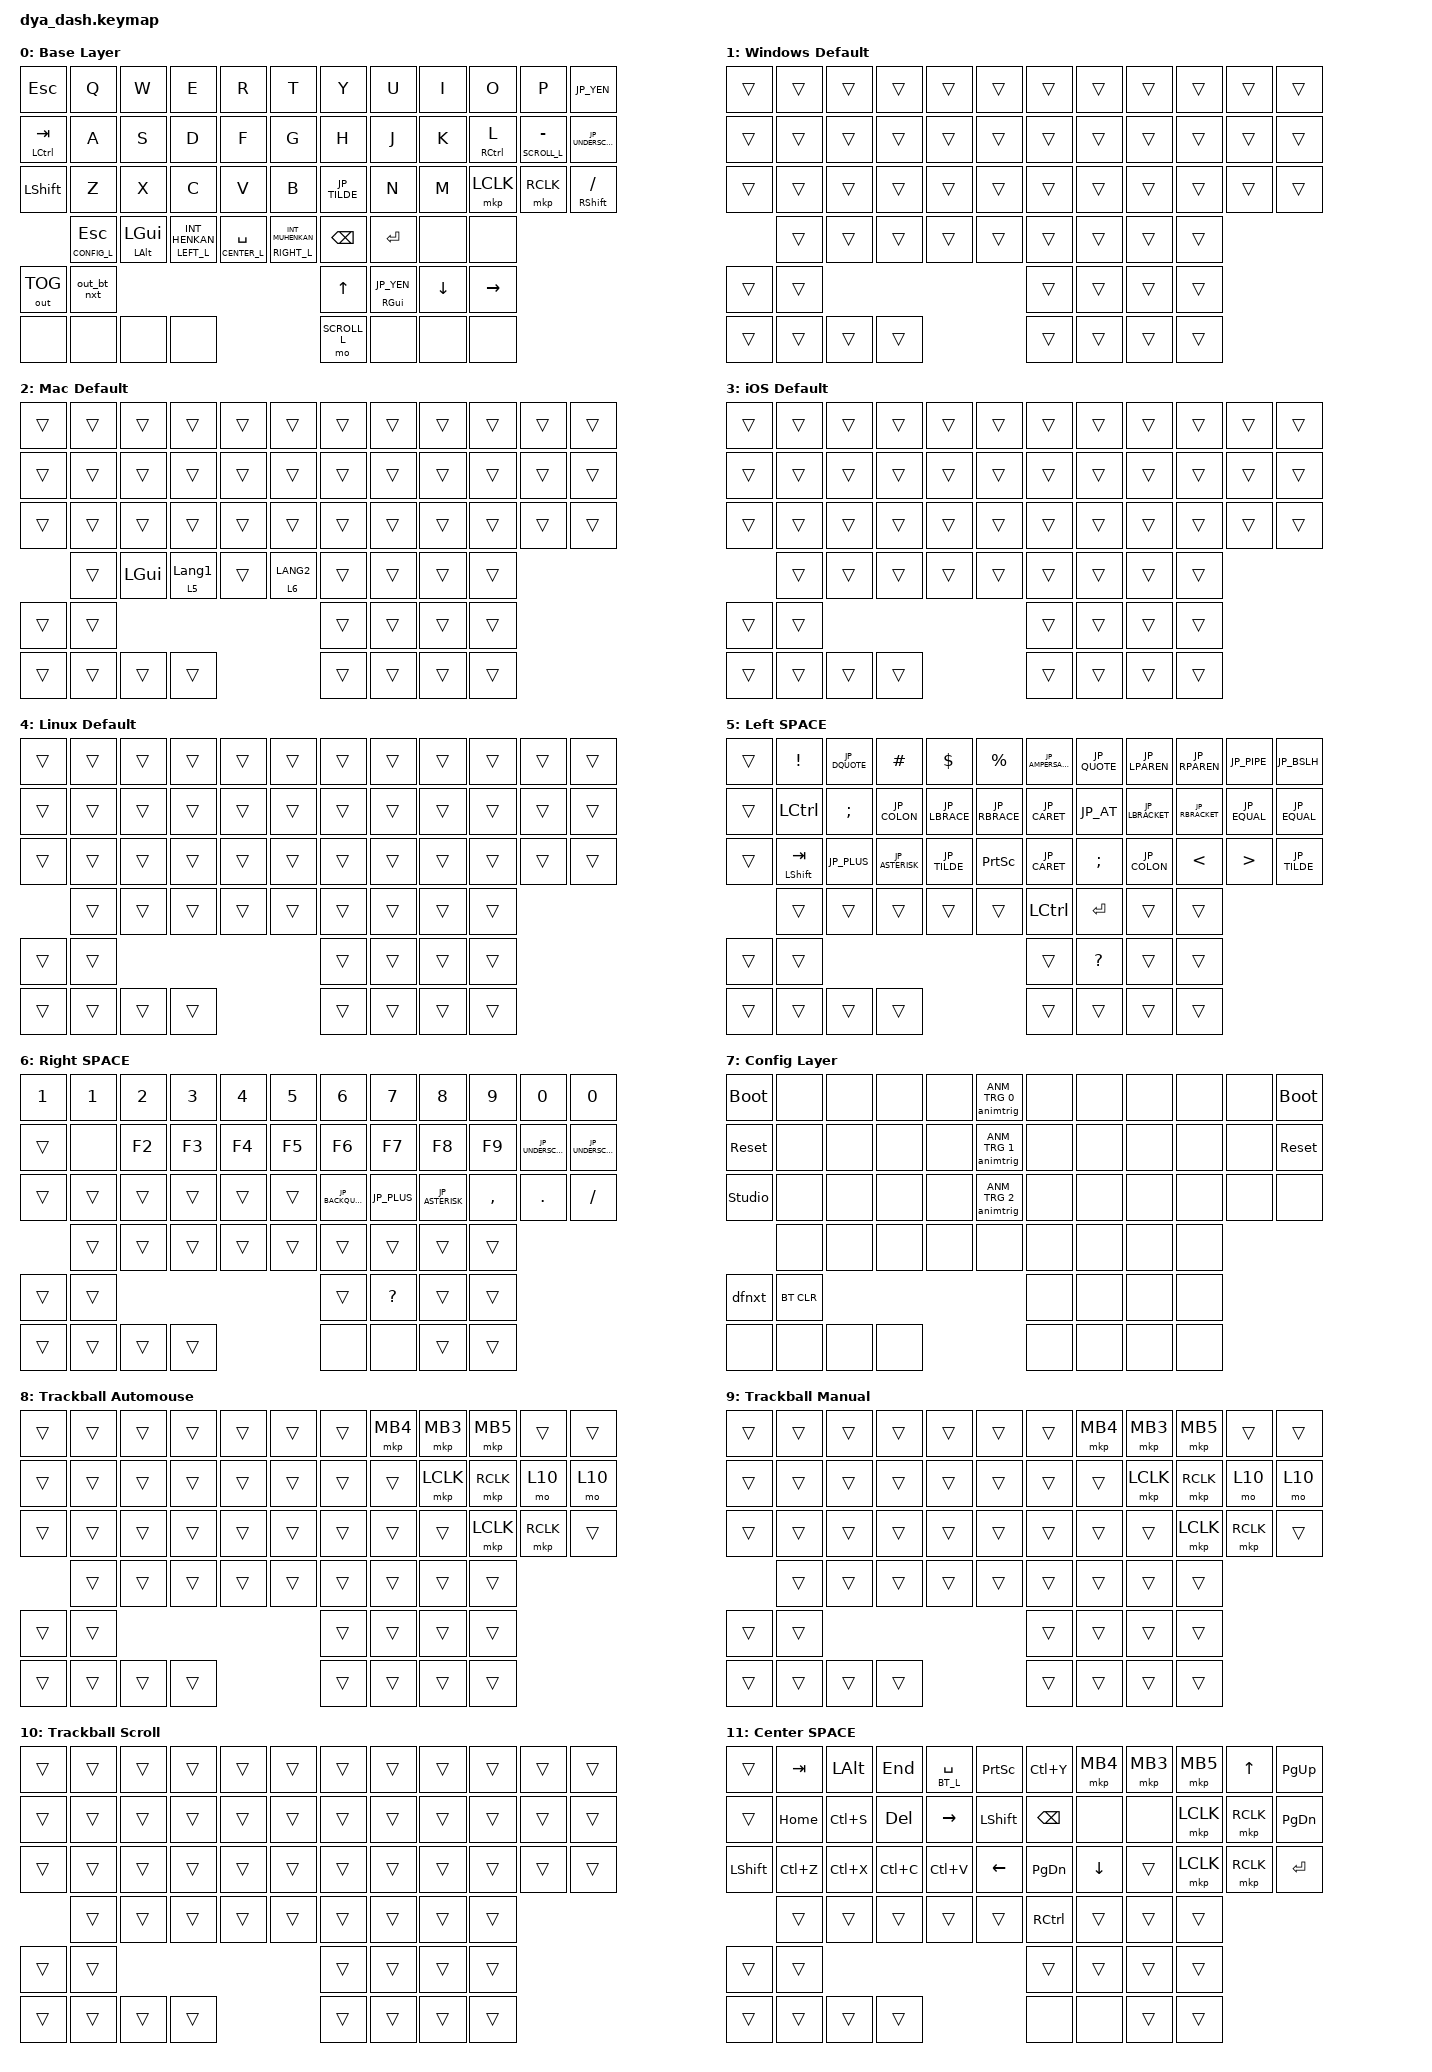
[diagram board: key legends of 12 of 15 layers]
#include <behaviors/mouse_move.dtsi>
#include <behaviors/animation_control.dtsi>
#include <behaviors/animation_trigger.dtsi>
#include <dt-bindings/zmk/mouse.h>
#include <dt-bindings/zmk_driver_animation/animation_control.h>
#include <dt-bindings/zmk_driver_animation/animation_trigger.h>
#include <dt-bindings/zmk_behavior_default_layer/default_layer.h>
#include <scroll-snap.dtsi> // スクロールスナップ用
#include <behaviors.dtsi>
#include <dt-bindings/zmk/bt.h>
#include <dt-bindings/zmk/keys.h>
#include <dt-bindings/zmk/outputs.h>
#include <dt-bindings/zmk/pointing.h>

#define JP_DQUOTE       AT                // "
#define JP_AMPERSAND    CARET             // &
#define JP_QUOTE        AMPERSAND         // '
#define JP_EQUAL        UNDER             // =
#define JP_CARET        EQUAL             // ^
#define JP_YEN          0x89              // ¥
#define JP_PLUS         COLON             // +
#define JP_TILDE        PLUS              // ~
#define JP_PIPE         LS(0x89)          // |
#define JP_AT           LEFT_BRACKET      // @
#define JP_COLON        SINGLE_QUOTE      // :
#define JP_ASTERISK     DOUBLE_QUOTES     // *
#define JP_BACKQUOTE    LEFT_BRACE        // `
#define JP_UNDERSCORE   LS(0x87)          // _
#define JP_LBRACKET     RIGHT_BRACKET     // [
#define JP_RBRACKET     BACKSLASH         // ]
#define JP_LPAREN       ASTERISK          // (
#define JP_RPAREN       LEFT_PARENTHESIS  // )
#define JP_LBRACE       RIGHT_BRACE       // {
#define JP_RBRACE       PIPE              // }
#define JP_KANA         LANGUAGE_1        // かな
#define JP_EISU         LANGUAGE_2        // 英数
#define JP_HANZEN       GRAVE             // 半角/全角
#define JP_BSLH  INT1         // (backslash)

// Layer definitions

#define DEFAULT_L		0
#define WINDOWS_L		1
#define MAC_L			2
#define IOS_L			3
#define LINUX_L			4
#define LEFT_L	 		5
#define RIGHT_L			6
#define CONFIG_L		7
#define TRACKBALL_L		8
#define TRACKBALL_L2	9
#define SCROLL_L		10
#define CENTER_L		11
#define CENTER2_L		12
#define EXT1_L			13
#define BT_L			14

// オートマウスレイヤー無効
//&trackball_listener {
//    input-processors = <
//    // TRACKBALL_L layer is activated when trackball is used.
//    // After 500ms of trackball inactivity, the layer is deactivated.
//    &zip_temp_layer TRACKBALL_L 500
//    // Example: Adjust sensitivity of trackball multiply by 1 and divide by 60.
//    // &zip_xy_scaler 1 60
//    >;
//};

&trackball_scroller {
    layers = <SCROLL_L>;

    // Example: adjust sensitivity of scroll multiply by 1 and divide by 60.

    input-processors = <
        &zip_xy_scaler 1 20
        &zip_xy_to_scroll_mapper
        &zip_scroll_snap
        &zip_scroll_transform INPUT_TRANSFORM_Y_INVERT
    >;
};

&trackball_listener_l { input-processors = <&zip_temp_layer TRACKBALL_L 500>; };

&trackball_scroller_l { layers = <SCROLL_L>; };

&zip_temp_layer { excluded-positions = <19 20 21 22 32 33 41 52 53 54 55 56 57 58 59>; };

&trackball_r { cpi = <500>; };

//&trackball_r { cpi = <800>; };

&trackball_l { cpi = <600>; };

/ {
    behaviors {
        // ctrl+h as backspace

        hbackspace: h_or_ctrl_backspace {
            compatible = "zmk,behavior-mod-morph";
            #binding-cells = <0>;
            bindings = <&kp H>, <&kp BACKSPACE>;

            mods = <(MOD_LCTL)>;
        };

        // ctrl+j as enter

        jenter: j_or_ctrl_enter {
            compatible = "zmk,behavior-mod-morph";
            #binding-cells = <0>;
            bindings = <&kp J>, <&kp ENTER>;

            mods = <(MOD_LCTL)>;
        };

        long_hold_mod_tap: long_hold_mod_tap {
            compatible = "zmk,behavior-hold-tap";
            label = "LONG_HOLD_MOD_TAP";
            bindings = <&kp>, <&kp>;

            #binding-cells = <2>;
            tapping-term-ms = <350>;
            quick-tap-ms = <0>;
            require-prior-idle-ms = <0>;
            flavor = "tap-preferred";
        };
    };

    macros {
        // Disconnect from all once for reliable connection to selected profile.
        // ZMK automatically reconnects to current profile right after disconnection.

        out_bt_nxt: out_bt_nxt {
            compatible = "zmk,behavior-macro";
            #binding-cells = <0>;
            wait-ms = <50>;
            bindings = <&out OUT_BLE &bt BT_NXT &bt BT_DISC 0 &bt BT_DISC 1 &bt BT_DISC 2 &bt BT_DISC 3 &bt BT_DISC 4>;
        };

        // Select specific BT device (0-4) and disconnect others

        out_bt_0: out_bt_0 {
            compatible = "zmk,behavior-macro";
            #binding-cells = <0>;
            wait-ms = <50>;
            bindings = <&out OUT_BLE &bt BT_SEL 0 &bt BT_DISC 1 &bt BT_DISC 2 &bt BT_DISC 3 &bt BT_DISC 4>;
        };

        out_bt_1: out_bt_1 {
            compatible = "zmk,behavior-macro";
            #binding-cells = <0>;
            wait-ms = <50>;
            bindings = <&out OUT_BLE &bt BT_SEL 1 &bt BT_DISC 0 &bt BT_DISC 2 &bt BT_DISC 3 &bt BT_DISC 4>;
        };

        out_bt_2: out_bt_2 {
            compatible = "zmk,behavior-macro";
            #binding-cells = <0>;
            wait-ms = <50>;
            bindings = <&out OUT_BLE &bt BT_SEL 2 &bt BT_DISC 0 &bt BT_DISC 1 &bt BT_DISC 3 &bt BT_DISC 4>;
        };

        out_bt_3: out_bt_3 {
            compatible = "zmk,behavior-macro";
            #binding-cells = <0>;
            wait-ms = <50>;
            bindings = <&out OUT_BLE &bt BT_SEL 3 &bt BT_DISC 0 &bt BT_DISC 1 &bt BT_DISC 2 &bt BT_DISC 4>;
        };

        out_bt_4: out_bt_4 {
            compatible = "zmk,behavior-macro";
            #binding-cells = <0>;
            wait-ms = <50>;
            bindings = <&out OUT_BLE &bt BT_SEL 4 &bt BT_DISC 0 &bt BT_DISC 1 &bt BT_DISC 2 &bt BT_DISC 3>;
        };

        // Change default layer for current profile to next layer

        dfnxt: dfnxt {
            compatible = "zmk,behavior-macro";
            #binding-cells = <0>;
            bindings = <&df DF_INC &animtrig ANM_TRG 2>;
        };
    };

    combos {
        compatible = "zmk,combos";

        // Right side's setting button shares input pin with arrow keys.
        // It works as a combo of two arrow keys.

        setting_r1 {
            timeout-ms = <10>;
            key-positions = <47 50>;
            bindings = <&kp C_VOL_DN>;
        };

        setting_r2 {
            timeout-ms = <10>;
            key-positions = <47 49>;
            bindings = <&kp C_VOL_UP>;
        };

        comma {
            bindings = <&kp COMMA>;
            key-positions = <31 32>;
            timeout-ms = <30>;
            require-prior-idle-ms = <20>;
        };

        dot {
            bindings = <&kp DOT>;
            key-positions = <32 33>;
            timeout-ms = <30>;
            require-prior-idle-ms = <20>;
        };

        asterisk {
            bindings = <&kp JP_ASTERISK>;
            key-positions = <18 19>;
            timeout-ms = <30>;
            require-prior-idle-ms = <20>;
        };

        plus {
            bindings = <&kp JP_PLUS>;
            key-positions = <30 31>;
            timeout-ms = <30>;
            require-prior-idle-ms = <20>;
        };

        mb3 {
            bindings = <&mkp MCLK>;
            key-positions = <7 8 9>;
            timeout-ms = <30>;
            require-prior-idle-ms = <20>;
        };

        mb4 {
            bindings = <&mkp MB4>;
            key-positions = <7 8>;
            timeout-ms = <30>;
        };

        mb5 {
            bindings = <&mkp MB5>;
            key-positions = <8 9>;
            timeout-ms = <30>;
            require-prior-idle-ms = <20>;
        };

        semicolon {
            bindings = <&kp SEMICOLON>;
            key-positions = <19 20>;
            timeout-ms = <30>;
            require-prior-idle-ms = <20>;
        };

        colon {
            bindings = <&kp JP_COLON>;
            key-positions = <20 21>;
            timeout-ms = <30>;
            require-prior-idle-ms = <20>;
        };

        shift_tab {
            bindings = <&kt LS(TAB)>;
            key-positions = <15 16>;
            timeout-ms = <30>;
            require-prior-idle-ms = <20>;
        };

        esc {
            bindings = <&kt ESC>;
            key-positions = <1 2>;
        };

        lctrl {
            bindings = <&kp LCTRL>;
            key-positions = <13 14>;
        };

        tab {
            bindings = <&kp TAB>;
            key-positions = <14 15>;
        };
    };

    keymap {
        compatible = "zmk,keymap";

        // template {
        //     bindings = <
        //         &trans      &trans      &trans      &trans      &trans      &trans      /**/ &trans      &trans      &trans      &trans      &trans      &trans
        //         &trans      &trans      &trans      &trans      &trans      &trans      /**/ &trans      &trans      &trans      &trans      &trans      &trans
        //         &trans      &trans      &trans      &trans      &trans      &trans      /**/ &trans      &trans      &trans      &trans      &trans      &trans
        //                     &trans      &trans      &trans      &trans      &trans      /**/ &trans      &trans      &trans      &trans
        //
        //         &trans      &trans                                                      /**/ &trans      &trans      &trans      &trans
        //         &trans      &trans      &trans      &trans                              /**/ &trans      &trans      &trans      &trans
        //     >;
        // };

        default_layer {
            display-name = "Base Layer";

            // --------------------------------------------------------------------------------------------------------------------------------------------------
            // |   TAB   |    Q    |    W    |    E       |    R    |    T        |            |    Y        |    U            |    I         |    O         |    P    |    ￥   |
            // |   CTRL  |    A    |    S    |    D       |    F    |    G        |            |    H        |    J            |    K         |    L         |    ;    |    -    |
            // |  SHIFT  |    Z    |    X    |    C       |    V    |    B        |            |    B        |    N            |    M         |    MB1       |    MB2  |    /    |
            //           |  CONFIG |   WIN   | LEFT_LAYER |  SPACE  | RIGHT_LAYER |            | BACKSPACE   |  ENTER          |   未使用     |   未使用      |
            // --------------------------------------------------------------------------------------------------------------------------------------------------
            // | BLE     |  USB    |                                                       | 未使用       | (右下)mt GUI ￥ |  未使用      |   未使用      |
            // | touch1  | touch2  | touch3  | touch 4 |                                   | touch1      | touch2          | touch3  | touch 4 |

            bindings = <
&kp ESC        &kp Q             &kp W              &kp E                  &kp R               &kp T                     &kp Y          &kp U                 &kp I     &kp O                       &kp P               &kp JP_YEN
&mt LCTRL TAB  &kp A             &kp S              &kp D                  &kp F               &kp G                     &kp H          &kp J                 &kp K     &long_hold_mod_tap RCTRL L  &lt SCROLL_L MINUS  &kp JP_UNDERSCORE
&kp LSHIFT     &kp Z             &kp X              &kp C                  &kp V               &kp B                     &kp JP_TILDE   &kp N                 &kp M     &mkp LCLK                   &mkp RCLK           &mt RIGHT_SHIFT SLASH
               &lt CONFIG_L ESC  &mt LALT LEFT_GUI  &lt LEFT_L INT_HENKAN  &lt CENTER_L SPACE  &lt RIGHT_L INT_MUHENKAN  &kp BACKSPACE  &kp ENTER             &none     &none
&out OUT_TOG   &out_bt_nxt                                                                                               &kp UP         &mt RIGHT_GUI JP_YEN  &kp DOWN  &kp RIGHT
&none          &none             &none              &none                                                                &mo SCROLL_L   &none                 &none     &none
            >;
        };

        windows_default_layer {
            display-name = "Windows Default";
            bindings = <
&trans  &trans  &trans  &trans  &trans  &trans  &trans  &trans  &trans  &trans  &trans  &trans
&trans  &trans  &trans  &trans  &trans  &trans  &trans  &trans  &trans  &trans  &trans  &trans
&trans  &trans  &trans  &trans  &trans  &trans  &trans  &trans  &trans  &trans  &trans  &trans
        &trans  &trans  &trans  &trans  &trans  &trans  &trans  &trans  &trans
&trans  &trans                                  &trans  &trans  &trans  &trans
&trans  &trans  &trans  &trans                  &trans  &trans  &trans  &trans
            >;
        };

        mac_default_layer {
            display-name = "Mac Default";
            bindings = <
&trans  &trans  &trans        &trans            &trans  &trans       &trans  &trans  &trans  &trans  &trans  &trans
&trans  &trans  &trans        &trans            &trans  &trans       &trans  &trans  &trans  &trans  &trans  &trans
&trans  &trans  &trans        &trans            &trans  &trans       &trans  &trans  &trans  &trans  &trans  &trans
        &trans  &kp LEFT_GUI  &lt 5 LANGUAGE_1  &trans  &lt 6 LANG2  &trans  &trans  &trans  &trans
&trans  &trans                                                       &trans  &trans  &trans  &trans
&trans  &trans  &trans        &trans                                 &trans  &trans  &trans  &trans
            >;
        };

        ios_default_layer {
            display-name = "iOS Default";
            bindings = <
&trans  &trans  &trans  &trans  &trans  &trans  &trans  &trans  &trans  &trans  &trans  &trans
&trans  &trans  &trans  &trans  &trans  &trans  &trans  &trans  &trans  &trans  &trans  &trans
&trans  &trans  &trans  &trans  &trans  &trans  &trans  &trans  &trans  &trans  &trans  &trans
        &trans  &trans  &trans  &trans  &trans  &trans  &trans  &trans  &trans
&trans  &trans                                  &trans  &trans  &trans  &trans
&trans  &trans  &trans  &trans                  &trans  &trans  &trans  &trans
            >;
        };

        linux_default_layer {
            display-name = "Linux Default";
            bindings = <
&trans  &trans  &trans  &trans  &trans  &trans  &trans  &trans  &trans  &trans  &trans  &trans
&trans  &trans  &trans  &trans  &trans  &trans  &trans  &trans  &trans  &trans  &trans  &trans
&trans  &trans  &trans  &trans  &trans  &trans  &trans  &trans  &trans  &trans  &trans  &trans
        &trans  &trans  &trans  &trans  &trans  &trans  &trans  &trans  &trans
&trans  &trans                                  &trans  &trans  &trans  &trans
&trans  &trans  &trans  &trans                  &trans  &trans  &trans  &trans
            >;
        };

        left_layer {
            display-name = "Left SPACE";

            // --------------------------------------------------------------------------------------------------------------------------------------------------------------------
            // |  ESC    |  !  |  @  |  #       |  $  |  %       |                           |  ^  |  &      |  *      |  (  |  )  |  \  |
            // |         |     |     |          |     |          |                           |  `  |  -      |  =      |  [  |  ]  |SHIFT|
            //           |     |     |          |     |          |                           |     |         |         |     |

            bindings = <
&trans  &kp EXCLAMATION     &kp JP_DQUOTE  &kp HASH         &kp DOLLAR     &kp PERCENT      &kp JP_AMPERSAND  &kp JP_QUOTE   &kp JP_LPAREN    &kp JP_RPAREN    &kp JP_PIPE       &kp JP_BSLH
&trans  &kp LCTRL           &kp SEMICOLON  &kp JP_COLON     &kp JP_LBRACE  &kp JP_RBRACE    &kp JP_CARET      &kp JP_AT      &kp JP_LBRACKET  &kp JP_RBRACKET  &kp JP_EQUAL      &kp JP_EQUAL
&trans  &mt LEFT_SHIFT TAB  &kp JP_PLUS    &kp JP_ASTERISK  &kp JP_TILDE   &kp PRINTSCREEN  &kp JP_CARET      &kp SEMICOLON  &kp JP_COLON     &kp LESS_THAN    &kp GREATER_THAN  &kp JP_TILDE
        &trans              &trans         &trans           &trans         &trans           &kp LCTRL         &kp ENTER      &trans           &trans
&trans  &trans                                                                              &trans            &kp QUESTION   &trans           &trans
&trans  &trans              &trans         &trans                                           &trans            &trans         &trans           &trans
            >;
        };

        right_layer {
            display-name = "Right SPACE";
            bindings = <
&kp NUMBER_1  &kp NUMBER_1  &kp NUMBER_2  &kp NUMBER_3  &kp NUMBER_4  &kp NUMBER_5  &kp NUMBER_6      &kp NUMBER_7  &kp NUMBER_8     &kp NUMBER_9  &kp NUMBER_0       &kp N0
&trans        &none         &kp F2        &kp F3        &kp F4        &kp F5        &kp F6            &kp F7        &kp F8           &kp F9        &kp JP_UNDERSCORE  &kp JP_UNDERSCORE
&trans        &trans        &trans        &trans        &trans        &trans        &kp JP_BACKQUOTE  &kp JP_PLUS   &kp JP_ASTERISK  &kp COMMA     &kp PERIOD         &kp SLASH
              &trans        &trans        &trans        &trans        &trans        &trans            &trans        &trans           &trans
&trans        &trans                                                                &trans            &kp QUESTION  &trans           &trans
&trans        &trans        &trans        &trans                                    &none             &none         &trans           &trans
            >;
        };

        config_layer {
            display-name = "Config Layer";
            bindings = <
&bootloader     &none       &none  &none  &none  &animtrig ANM_TRG 0  &none  &none  &none  &none  &none  &bootloader
&sys_reset      &none       &none  &none  &none  &animtrig ANM_TRG 1  &none  &none  &none  &none  &none  &sys_reset
&studio_unlock  &none       &none  &none  &none  &animtrig ANM_TRG 2  &none  &none  &none  &none  &none  &none
                &none       &none  &none  &none  &none                &none  &none  &none  &none
&dfnxt          &bt BT_CLR                                            &none  &none  &none  &none
&none           &none       &none  &none                              &none  &none  &none  &none
            >;
        };

        trackball_layer {
            display-name = "Trackball Automouse";
            bindings = <
&trans  &trans  &trans  &trans  &trans  &trans  &trans  &mkp MB4  &mkp MB3   &mkp MB5   &trans     &trans
&trans  &trans  &trans  &trans  &trans  &trans  &trans  &trans    &mkp LCLK  &mkp RCLK  &mo 10     &mo 10
&trans  &trans  &trans  &trans  &trans  &trans  &trans  &trans    &trans     &mkp LCLK  &mkp RCLK  &trans
        &trans  &trans  &trans  &trans  &trans  &trans  &trans    &trans     &trans
&trans  &trans                                  &trans  &trans    &trans     &trans
&trans  &trans  &trans  &trans                  &trans  &trans    &trans     &trans
            >;
        };

        trackball_layer2 {
            display-name = "Trackball Manual";
            bindings = <
&trans  &trans  &trans  &trans  &trans  &trans  &trans  &mkp MB4  &mkp MB3   &mkp MB5   &trans     &trans
&trans  &trans  &trans  &trans  &trans  &trans  &trans  &trans    &mkp LCLK  &mkp RCLK  &mo 10     &mo 10
&trans  &trans  &trans  &trans  &trans  &trans  &trans  &trans    &trans     &mkp LCLK  &mkp RCLK  &trans
        &trans  &trans  &trans  &trans  &trans  &trans  &trans    &trans     &trans
&trans  &trans                                  &trans  &trans    &trans     &trans
&trans  &trans  &trans  &trans                  &trans  &trans    &trans     &trans
            >;
        };

        scroll_layer {
            display-name = "Trackball Scroll";
            bindings = <
&trans  &trans  &trans  &trans  &trans  &trans  &trans  &trans  &trans  &trans  &trans  &trans
&trans  &trans  &trans  &trans  &trans  &trans  &trans  &trans  &trans  &trans  &trans  &trans
&trans  &trans  &trans  &trans  &trans  &trans  &trans  &trans  &trans  &trans  &trans  &trans
        &trans  &trans  &trans  &trans  &trans  &trans  &trans  &trans  &trans
&trans  &trans                                  &trans  &trans  &trans  &trans
&trans  &trans  &trans  &trans                  &trans  &trans  &trans  &trans
            >;
        };

        center_layer {
            display-name = "Center SPACE";
            bindings = <
&trans          &kp TAB    &kp LEFT_ALT  &kp END    &lt BT_L SPACE   &kp PRINTSCREEN  &kp LC(Y)      &mkp MB4        &mkp MB3  &mkp MB5   &kp UP_ARROW  &kp PAGE_UP
&trans          &kp HOME   &kp LC(S)     &kp DEL    &kp RIGHT_ARROW  &kp LEFT_SHIFT   &kp BACKSPACE  &none           &none     &mkp LCLK  &mkp RCLK     &kp PAGE_DOWN
&kp LEFT_SHIFT  &kp LC(Z)  &kp LC(X)     &kp LC(C)  &kp LC(V)        &kp LEFT_ARROW   &kp PAGE_DOWN  &kp DOWN_ARROW  &trans    &mkp LCLK  &mkp RCLK     &kp ENTER
                &trans     &trans        &trans     &trans           &trans           &kp RCTRL      &trans          &trans    &trans
&trans          &trans                                                                &trans         &trans          &trans    &trans
&trans          &trans     &trans        &trans                                       &none          &none           &trans    &trans
            >;
        };

        center2_layer {
            display-name = "Center SPACE(mac)";
            bindings = <
&trans          &kp TAB    &kp LEFT_ALT  &kp END    &lt BT_L SPACE   &kp PRINTSCREEN  &kp LC(Y)      &mkp MB4        &mkp MB3  &mkp MB5   &kp UP_ARROW  &kp PAGE_UP
&trans          &kp HOME   &kp LC(S)     &kp DEL    &kp RIGHT_ARROW  &kp LEFT_SHIFT   &kp BACKSPACE  &none           &none     &mkp LCLK  &mkp RCLK     &kp PAGE_DOWN
&kp LEFT_SHIFT  &kp LC(Z)  &kp LC(X)     &kp LC(C)  &kp LC(V)        &kp LEFT_ARROW   &kp PAGE_DOWN  &kp DOWN_ARROW  &trans    &mkp LCLK  &mkp RCLK     &kp ENTER
                &trans     &trans        &trans     &trans           &trans           &kp RCTRL      &trans          &trans    &trans
&trans          &trans                                                                &trans         &trans          &trans    &trans
&trans          &trans     &trans        &trans                                       &none          &none           &trans    &trans
            >;
        };

        extra1 {
            display-name = "Extra";
            bindings = <
&trans  &trans  &trans  &trans  &trans  &trans  &out_bt_0  &out_bt_1  &out_bt_2  &out_bt_3  &out_bt_4  &trans
&trans  &trans  &trans  &trans  &trans  &trans  &trans     &trans     &trans     &trans     &trans     &trans
&trans  &trans  &trans  &trans  &trans  &trans  &trans     &trans     &trans     &trans     &trans     &trans
        &trans  &trans  &trans  &trans  &trans  &trans     &trans     &trans     &trans
&trans  &trans                                  &trans     &trans     &trans     &trans
&trans  &trans  &trans  &trans                  &trans     &trans     &trans     &trans
            >;
        };

        bluetooth_layer {
            display-name = "Bluetooth";
            bindings = <
&trans  &trans  &trans  &trans  &trans  &trans  &out_bt_0           &out_bt_1  &out_bt_2  &out_bt_3  &out_bt_4  &trans
&trans  &trans  &trans  &trans  &trans  &trans  &trans              &trans     &trans     &trans     &trans     &trans
&trans  &trans  &trans  &trans  &trans  &trans  &kp LC(RA(DELETE))  &trans     &trans     &trans     &trans     &trans
        &trans  &trans  &trans  &trans  &trans  &trans              &trans     &trans     &trans
&trans  &trans                                  &trans              &trans     &trans     &trans
&trans  &trans  &trans  &trans                  &trans              &trans     &trans     &trans
            >;
        };
    };
};
